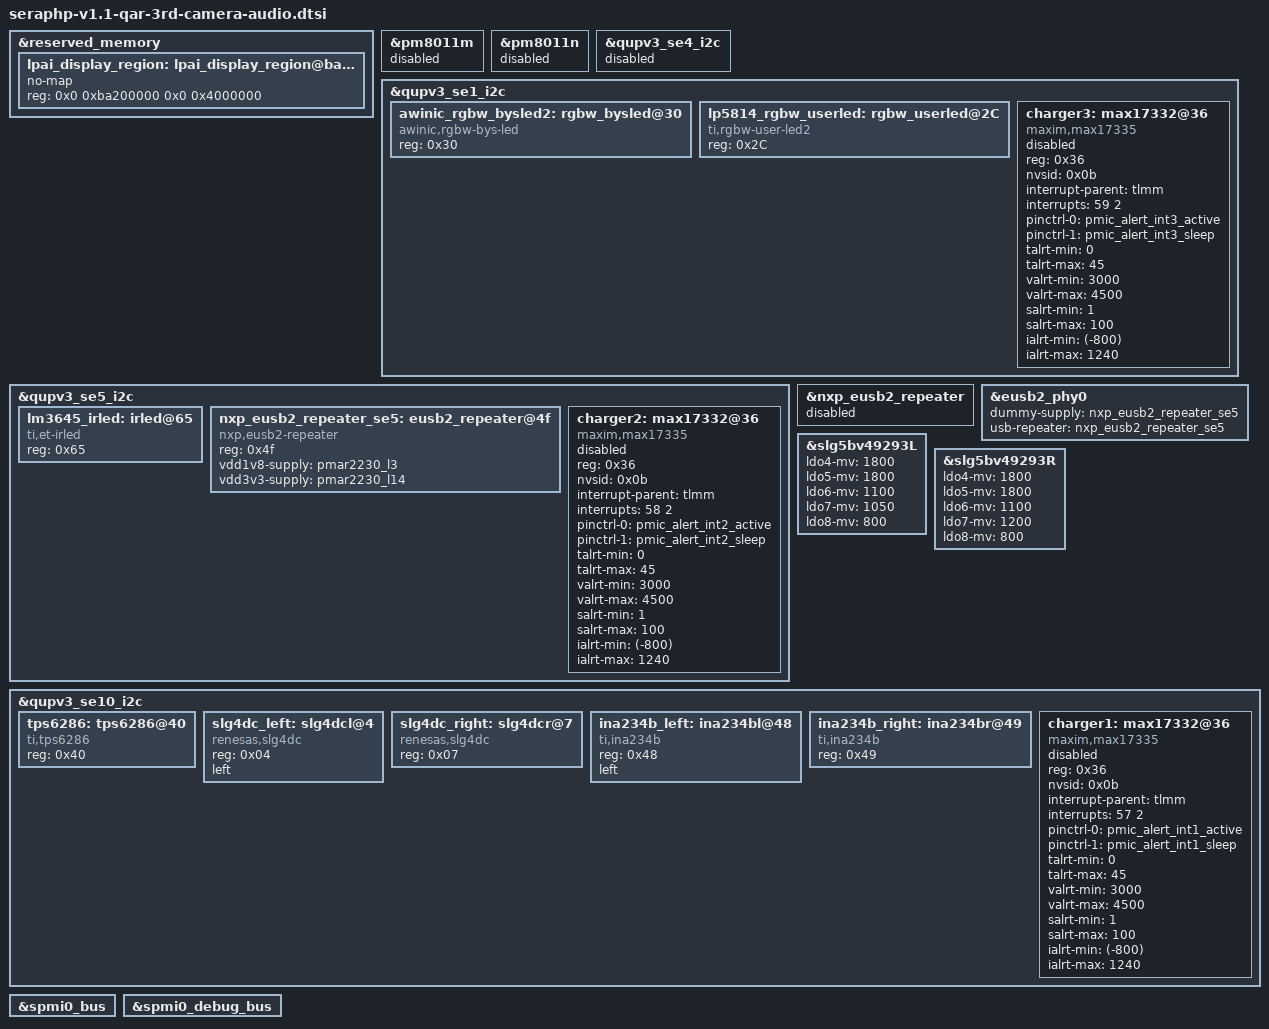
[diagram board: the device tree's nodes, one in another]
// SPDX-License-Identifier: BSD-3-Clause
/*
 * Copyright (c) Qualcomm Technologies, Inc. and/or its subsidiaries.
 */

#include "seraphp-qar-camera-audio.dtsi"
#include "seraphp-pmslg5.dtsi"

&reserved_memory {
	lpai_display_region: lpai_display_region@ba200000 {
		no-map;
		reg = <0x0 0xba200000 0x0 0x4000000>;
	};
};

&pm8011m {
	status = "disabled";
	/delete-node/ pm8011m_reset;
};

&pm8011n {
	status = "disabled";
	/delete-node/ pm8011n_reset;
};


&qupv3_se4_i2c {
	status = "disabled";
	/delete-node/ rgbw_bysled@30;
	/delete-node/ rgbw_userled@33;
};

&qupv3_se1_i2c {
	status = "okay";
	#address-cells = <1>;
	#size-cells = <0>;

	awinic_rgbw_bysled2: rgbw_bysled@30 {
		compatible = "awinic,rgbw-bys-led";
		reg = <0x30>;
	};

	lp5814_rgbw_userled: rgbw_userled@2C {
		compatible = "ti,rgbw-user-led2";
		reg = <0x2C>;
	};
};

&qupv3_se5_i2c {
	status = "okay";
	#address-cells = <1>;
	#size-cells = <0>;

	lm3645_irled: irled@65 {
		compatible = "ti,et-irled";
		reg = <0x65>;
	};

	nxp_eusb2_repeater_se5: eusb2_repeater@4f {
		compatible = "nxp,eusb2-repeater";
		reg = <0x4f>;
		vdd1v8-supply = <&pmar2230_l3>;
		vdd3v3-supply = <&pmar2230_l14>;
	};
};

&nxp_eusb2_repeater {
	status = "disabled";
};

&eusb2_phy0 {
	dummy-supply = <&nxp_eusb2_repeater_se5>;
	usb-repeater = <&nxp_eusb2_repeater_se5>;
};

&slg5bv49293L {
	ldo4-mv = <1800>;
	ldo5-mv = <1800>;
	ldo6-mv = <1100>;
	ldo7-mv = <1050>;
	ldo8-mv = <800>;
};

&slg5bv49293R {
	ldo4-mv = <1800>;
	ldo5-mv = <1800>;
	ldo6-mv = <1100>;
	ldo7-mv = <1200>;
	ldo8-mv = <800>;
};

&qupv3_se10_i2c {
	status = "okay";
	#address-cells = <1>;
	#size-cells = <0>;

	tps6286: tps6286@40 {
		compatible = "ti,tps6286";
		reg = <0x40>;
	};

	slg4dc_left: slg4dcl@4 {
		compatible = "renesas,slg4dc";
		reg = <0x04>;
		left;
	};

	slg4dc_right: slg4dcr@7 {
		compatible = "renesas,slg4dc";
		reg = <0x07>;
	};

	ina234b_left: ina234bl@48 {
		compatible = "ti,ina234b";
		reg = <0x48>;
		left;
	};

	ina234b_right: ina234br@49 {
		compatible = "ti,ina234b";
		reg = <0x49>;
	};

	charger1: max17332@36 {
		compatible = "maxim,max17335";
		reg = <0x36>;
		status = "disabled";
		nvsid = <0x0b>;
		interrupt-parent = <&tlmm>;
		interrupts = <57 2>;
		pinctrl-names = "default", "sleep";
		pinctrl-0 = <&pmic_alert_int1_active>;
		pinctrl-1 = <&pmic_alert_int1_sleep>;
		talrt-min = <0>;
		talrt-max = <45>;
		valrt-min   = <3000>;       /* mV */
		valrt-max   = <4500>;       /* mV */
		salrt-min   = <1>;          /* Percent */
		salrt-max   = <100>;        /* Percent */
		ialrt-min   = <(-800)>;     /* mA */
		ialrt-max   = <1240>;       /* mA */
	};
};

&qupv3_se5_i2c {

	#address-cells = <1>;
	#size-cells = <0>;

	charger2: max17332@36 {
		compatible = "maxim,max17335";
		reg = <0x36>;
		status = "disabled";
		nvsid = <0x0b>;
		interrupt-parent = <&tlmm>;
		interrupts = <58 2>;
		pinctrl-names = "default", "sleep";
		pinctrl-0 = <&pmic_alert_int2_active>;
		pinctrl-1 = <&pmic_alert_int2_sleep>;
		talrt-min = <0>;
		talrt-max = <45>;
		valrt-min   = <3000>;       /* mV */
		valrt-max   = <4500>;       /* mV */
		salrt-min   = <1>;          /* Percent */
		salrt-max   = <100>;        /* Percent */
		ialrt-min   = <(-800)>;     /* mA */
		ialrt-max   = <1240>;       /* mA */
	};
};

&qupv3_se1_i2c {

	#address-cells = <1>;
	#size-cells = <0>;

	charger3: max17332@36 {
		compatible = "maxim,max17335";
		reg = <0x36>;
		status = "disabled";
		nvsid = <0x0b>;
		interrupt-parent = <&tlmm>;
		interrupts = <59 2>;
		pinctrl-names = "default", "sleep";
		pinctrl-0 = <&pmic_alert_int3_active>;
		pinctrl-1 = <&pmic_alert_int3_sleep>;
		talrt-min = <0>;
		talrt-max = <45>;
		valrt-min   = <3000>;       /* mV */
		valrt-max   = <4500>;       /* mV */
		salrt-min   = <1>;          /* Percent */
		salrt-max   = <100>;        /* Percent */
		ialrt-min   = <(-800)>;     /* mA */
		ialrt-max   = <1240>;       /* mA */
	};
};

&spmi0_bus {
	/delete-node/ pm8010@c;
	/delete-node/ pm8010@d;
};

&spmi0_debug_bus {
	/delete-node/ qcom,pm8010-debug@c;
	/delete-node/ qcom,pm8010-debug@d;
};
